# apollo510 register map
Vendor: Ambiq Micro; Series: Apollo; File version: 1.0
CPU: CM55 r1p1, little endian, MPU, FPU, double-precision FPU, DSP, I-cache, D-cache, VTOR, ITCM, DTCM, 4 interrupt priority bits, 0 interrupts, 8 SAU regions
Registers are 32-bit, read-write, reset 0x0 unless marked. A register's access mark holds for its fields unless they carry their own. Offsets are from the block's base; [hi:lo] are bit positions; 'fields as' and 'values as' point back to an identical list.

## I2S0 — I2S Master/Slave Module
Base 0x40208000
Same registers: I2S1 0x40209000
0x00 RXDATA — Read only access to the i2S receive data
  [31:0] RXSAMPLE — 32b audio sample from the internal receive FIFO. MSB is always in bit 31
0x04 RXCHANID — Read only received channel identification register
  [7:0] RXCHANID — Channel ID value 0-255.
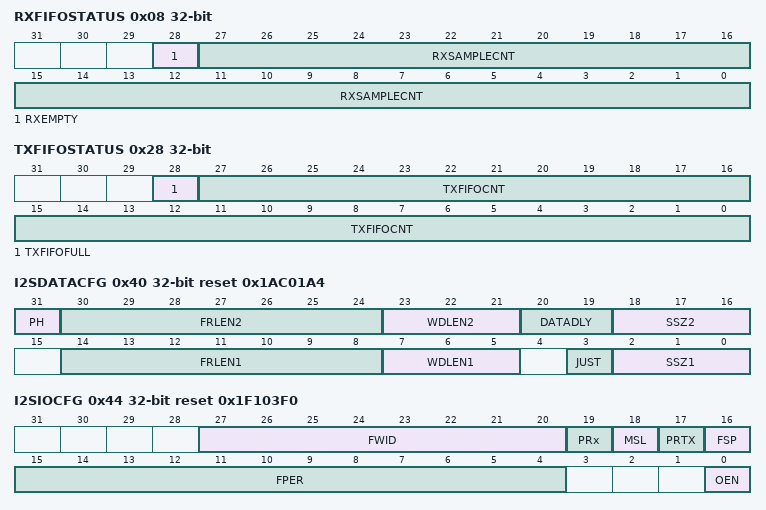
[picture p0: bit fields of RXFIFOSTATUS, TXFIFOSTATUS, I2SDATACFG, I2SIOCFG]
0x08 RXFIFOSTATUS — Holds the number of samples currently in the receive FIFO, and the empty condition flag
  [28] RXEMPTY — Receive FIFO empty bit. a 1 indicates the receive FIFO is empty.
  [27:0] RXSAMPLECNT — The count of the number of samples currently in the receive FIFO.
0x0C RXFIFOSIZE — Holds the size of the receive FIFO in samples
  [31:0] SIZE — Size of the receive FIFO in units of i2S samples. Read only value.
0x10 RXUPPERLIMIT — The number of samples required to be in the RX FIFO before asserting the RX_FFi interrupt bit
  [31:0] SIZE — When the I2S sample count stored within the receive FIFO reaches this value or is larger, the interrupt RX_FFi bit is asserted.
0x20 TXDATA — Write only register to hold the i2S sample to transmit via the write FIFO
  [31:0] TXSAMPLE — 32b I2S sample to send out of the I2S module via the external pins. All sample have the MSB in bit 31 regardless of number of bits per sample and data justification
0x24 TXCHANID — Channel ID used for the next audio sample to be written to the data transmission register
  [7:0] TXCHANID — Channel ID value 0-255.
0x28 TXFIFOSTATUS — Holds the number of samples currently in the transmit FIFO, and the full condition flag
  [28] TXFIFOFULL — Transmit FIFO full bit. a 1 indicates the transmit FIFO is full.
  [27:0] TXFIFOCNT — The count of the number of samples currently in the transmit FIFO.
0x2C TXFIFOSIZE — Holds the size of the transmit FIFO in samples
  [31:0] SIZE — Size of the transmit FIFO in units of I2S samples. Read only value.
0x30 TXLOWERLIMIT — Minimum number of samples have been reached in the transmit FIFO.
  [31:0] SIZE — When the number of sample in the TX FIFO goes below this value, the interrupt TX_FFi bit is asserted.
0x40 I2SDATACFG reset 0x1AC01A4 — Specifies the data format of I2S sub frames
  [31] PH — Read Phase Bit. 0: Single Phase frame; 1: Dual-Phase frame.
  [30:24] FRLEN2 — Number of channels in phase 2; 0: 1 Channel in phase 2, .. 0x7F: 128 channels in phase 2
    0=1CHLS (One channel in phase 2.); 1=2CHLS (Two channels in phase 2.); 2=3CHLS (Three channels in phase 2.); 3=4CHLS (Four channels in phase 2.); 4=5CHLS (Five channels in phase 2.); 5=6CHLS (Six channels in phase 2.); 6=7CHLS (Seven channels in phase 2.); 7=8CHLS (Eight channels in phase 2.); 127=128CHLS (128 channels in phase 2.)
  [23:21] WDLEN2 — Receive channel length in bits for phase 2. 0: 8b, 1: 12b, 2: 16b, 3: 20b, 4: 24b, 5: 32b, 6,7: Reserved
    0=8b (Receive channel length is 8 bits for phase 2.); 1=12b (Receive channel length is 12 bits for phase 2.); 2=16b (Receive channel length is 16 bits for phase 2.); 3=20b (Receive channel length is 20 bits for phase 2.); 4=24b (Receive channel length is 24 bits for phase 2.); 5=32b (Receive channel length is 32 bits for phase 2.)
  [20:19] DATADLY — Receive data delay bit count. Valid values are 0-2, 3 is reserved.
  [18:16] SSZ2 — Receive audio sample length for phase 2. 0: 8b, 1: 12b, 2: 16b, 3: 20b, 4: 24b, 5: 32b, 6,7: Reserved
    0=8b (Receive audio sample length is 8 bits for phase 2.); 1=12b (Receive audio sample length is 12 bits for phase 2.); 2=16b (Receive audio sample length is 16 bits for phase 2.); 3=20b (Receive audio sample length is 20 bits for phase 2.); 4=24b (Receive audio sample length is 24 bits for phase 2.); 5=32b (Receive audio sample length is 32 bits for phase 2.)
  [14:8] FRLEN1 — Number of channels in phase 1; 0: 1 Channel in phase 2, .. 0x7F: 128 channels in phase 1
    0=1CHLS (One channel in phase 1.); 1=2CHLS (Two channels in phase 1.); 2=3CHLS (Three channels in phase 1.); 3=4CHLS (Four channels in phase 1.); 4=5CHLS (Five channels in phase 1.); 5=6CHLS (Six channels in phase 1.); 6=7CHLS (Seven channels in phase 1.); 7=8CHLS (Eight channels in phase 1.); 127=128CHLS (128 channels in phase 1.)
  [7:5] WDLEN1 — Receive channel length in bits for phase 2. 0: 8b, 1: 12b, 2: 16b, 3: 20b, 4: 24b, 5: 32b, 6,7: Reserved
    0=8b (Receive channel length is 8 bits for phase 1.); 1=12b (Receive channel length is 12 bits for phase 1.); 2=16b (Receive channel length is 16 bits for phase 1.); 3=20b (Receive channel length is 20 bits for phase 1.); 4=24b (Receive channel length is 24 bits for phase 1.); 5=32b (Receive channel length is 32 bits for phase 1.)
  [3] JUST — Audio sample justification. 0: Left-justified, 1: Right-justified
  [2:0] SSZ1 — Receive audio sample length for phase 1. 0: 8b, 1: 12b, 2: 16b, 3: 20b, 4: 24b, 5: 32b, 6,7: Reserved
    0=8b (Receive audio sample length is 8 bits for phase 1.); 1=12b (Receive audio sample length is 12 bits for phase 1.); 2=16b (Receive audio sample length is 16 bits for phase 1.); 3=20b (Receive audio sample length is 20 bits for phase 1.); 4=24b (Receive audio sample length is 24 bits for phase 1.); 5=32b (Receive audio sample length is 32 bits for phase 1.)
0x44 I2SIOCFG reset 0x1F103F0 — Specified polarity and clock configuration of the I2S IPB clocks and IO signals
  [27:20] FWID — period of fsync/lr_clk in units of sclks
  [19] PRx — Receive clock edge polarity bit. 0: sdata is sampled on the rising edge of sclk. 1: sdata is sampled on the falling edge of sclk.
  [18] MSL — Master/Slave clock configuration. 0: External clock(sclk and lr_clk provided externally). 1: Internal clock (sclk and lr_clk sourced internally).
  [17] PRTX — Transmit clock edge polarity bit. 0: sdata is transmitted starting from the falling edge of sclk. 1: sdata is transmitted starting from the rising edge of sclk.
  [16] FSP — Polarity of fsync/lr_clk signal. 0: Active high. 1: Active low
  [15:4] FPER — Frame period in units of sclk. Period is FPER + 1 sclks in length. 0: 1 sclk, 0x3F: 64 sclks
  [0] OEN — Output enable for SDATA output
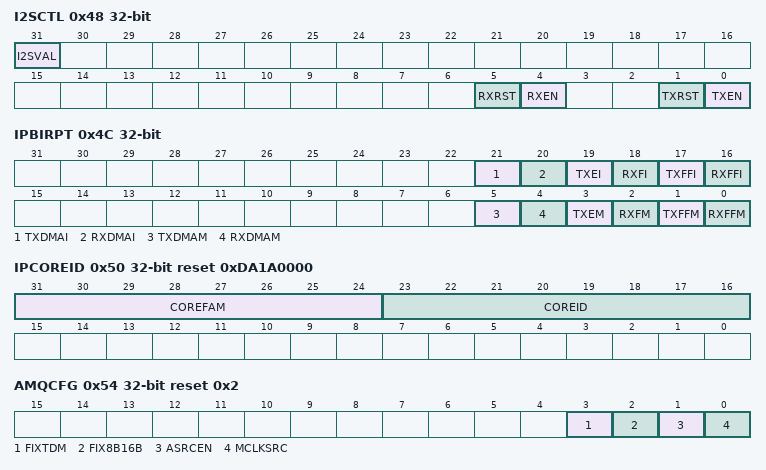
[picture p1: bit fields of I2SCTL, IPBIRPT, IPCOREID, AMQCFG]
0x48 I2SCTL — Specified polarity and clock configuration of the I2S IPB clocks and IO signals
  [31] I2SVAL — I2S validity bit mode. 1: RX data stored only when validity mask condition is asserted. 0: No validity mask conditions checking is done.
  [5] RXRST — Active high receiver reset signal. 1: Flush the RX FIFO
  [4] RXEN — Receive enable control. 1: Enables capture of serial audio, starting with first channel. 0: No receive data captured. For Full duplex operation, RXEN and TXEN MUST be set in a single register write access, or the Slave FSM may ignore one of the bit-field read-modify-write accesses. TXRST and RXRST must be cleared in advance.
  [1] TXRST — Transmit reset signal. 1 will reset the TX side registers and flush the TX FIFO.
  [0] TXEN — Transmit enable signal. 1 will enable the transmission of serial audio. For Full duplex operation, RXEN and TXEN MUST be set in a single register write access, or the Slave FSM may ignore one of the bit-field read-modify-write accesses. TXRST and RXRST must be cleared in advance.
0x4C IPBIRPT — Additional mask and status registers for the IPB core.
  [21] TXDMAI — TX dma interrupt
  [20] RXDMAI — RX dma interrupt
  [19] TXEI — TX Empty interrupt. TX unit attempted to read an empty FIFO
  [18] RXFI — RX Full interrupt. RX unit attempted to write to a full FIFO
  [17] TXFFI — Transmit fifo low limit interrupt
  [16] RXFFI — Receive fifo high limit interrupt
  [5] TXDMAM — Transmit FIFO interrupt mask. Will assert interrupt when = 1 and cimdmareq_tx is asserted
  [4] RXDMAM — Receive FIFO interrupt mask. Will assert interrupt when = 1 and cimdmareq_rx is asserted
  [3] TXEM — Transmit FIFO interrupt mask. Will assert interrupt when = 1 and TXEI is asserted
  [2] RXFM — Receive FIFO interrupt mask. Will assert interrupt when = 1 and RXFI is asserted
  [1] TXFFM — Transmit FIFO interrupt mask. Will assert interrupt when = 1 and TXFFI is asserted
  [0] RXFFM — Receive FIFO interrupt mask. Will assert interrupt when = 1 and RXFFI is asserted
0x50 IPCOREID reset 0xDA1A0000 — Returns the core ID of the IPB core, and used to write the I2S validity mask.
  [31:24] COREFAM — Core Family. Also bit 31 is used to set the I2S validity bit when a write is done.
  [23:16] COREID — Core ID of the IPB core
0x54 AMQCFG reset 0x2 — Control the enablement of the ASRC module and the source of the MCLK used in the IPB core.
  [3] FIXTDM — FIXTDM bug 1: Enabled. 0: Disabled/Bypassed
  [2] FIX8B16B — FIX8B16B bug 1: Enabled. 0: Disabled/Bypassed
  [1] ASRCEN — ASRC sub module enable. 0: Enabled. 1: Disabled/Bypassed
  [0] MCLKSRC — MCLK source. 1: Output of nco_clk divider. 0: MCLK from ambiq clock configuration directly
0x60 INTDIV — Integer divide value for the nco_clk divider
  [31:0] INTDIV — Integer divide value for internal clock divider
0x64 FRACDIV — Fractional divide value for the nco_clk divider
  [31:0] FRACDIV — Fractional divide value for internal clock divider
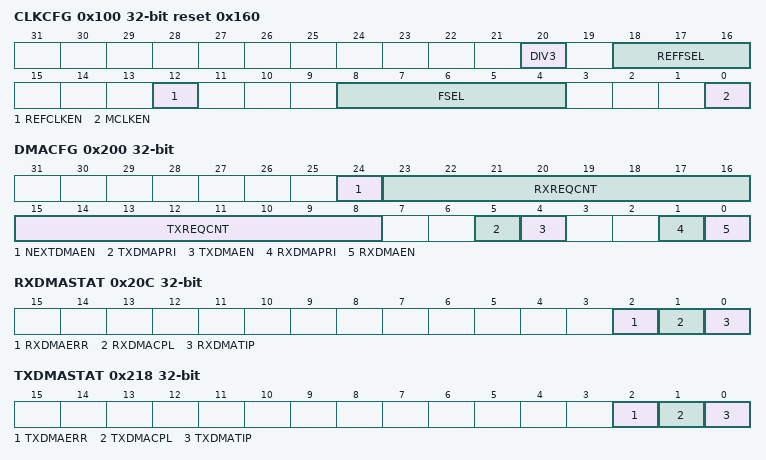
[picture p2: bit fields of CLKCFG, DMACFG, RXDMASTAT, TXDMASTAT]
0x100 CLKCFG reset 0x160 — Provides clock selection and control for I2S clocks
  [20] DIV3 — 0: no change to the clock selected by FSEL 1: frequency divide-by-3 of the clock selected by FSEL
  [18:16] REFFSEL — FUTURE USE Select the input clock frequency for the ref_clk. 0: HFRC_48MHz 1: HFRC_48MHz_GATED 2: XT_24MHz 3: HFRC2_48MHz
  [12] REFCLKEN — FUTURE USE Enable for the reference clock
  [8:4] FSEL — Select the input clock frequency for the MCLK.Whenever changing the clock source here, the MISC_HFRC2FRC bit in the CLKGEN module must first be set. The sequence for changing the clock source regardless of clock selection is to first force HFRC2 on by setting the CLKGEN_MISC_HFRC2FRC bit, select the clock source in this field, clear the CLKGEN_MISC_HFRC2FRC bit only if HFRC2 is NOT selected, and then engage the peripheral.If HFRC2 is the clock source, then shutting the module down cleanly requires switching to HFRC, for example, and then disabling the HFRC2 by clearing the CLKGEN_MISC_HFRC2FRC bit. 0: HFRC2_62MHz 1: HFRC2_31MHz 2: HFRC2_16MHz 3: HFRC2_8MHz 4: HFRC2_4MHz 5: HFRC2_2MHz 6: HFRC2_977KHz 7: HFRC2_488KHz 8: HFRC_24MHz 9: HFRC_12MHz 10: HFRC_6MHz 11: HFRC_3MHz 12: HFRC_1_5MHz 13: HFRC_750KHz 14: HFRC_375KHz 15: XTHS_EXTREF_CLK 16: XTHS_16MHz 17: XTHS_8MHz 18: XTHS_4MHz 19: XTHS_2MHz 20: XTHS_1MHz 21: XTHS_500KHz 22: HFRC_48MHz
  [0] MCLKEN — Enable for the master audio clock.
0x200 DMACFG — Configuration control of the DMA process, including the direction of DMA, and enablement of DMA
  [24] NEXTDMAEN — Enable next DMA job auto-load feature
  [23:16] RXREQCNT — Number of blocks of samples transferred before asserting the RXREQCNT interrupt signal. A block is 8 samples. The interrupt will assert if enabled and after RXREQCNT blocks of data has been transferred from the I2S into the device. A value of 0 will cause the assertion of the interrupt for every block of transfer done.
  [15:8] TXREQCNT — Number of blocks of samples transferred before asserting the TXREQCNT interrupt signal. A block is 8 samples. The interrupt will assert if enabled and after TXREQCNT blocks of data has been transferred to the I2S module from the device. A value of 0 will cause the assertion of the interrupt for every block of transfer done.
  [5] TXDMAPRI — Sets the Priority of the TXDMA request
    0=LOW (Low Priority (service as best effort)); 1=HIGH (High Priority (service immediately))
  [4] TXDMAEN — DMA Enable for TX channel. Setting this bit to EN will start the DMA operation. This should be the last DMA related register set prior to issuing the command
    0=DIS (Disable TXDMA Function); 1=EN (Enable TXDMA Function)
  [1] RXDMAPRI — Sets the Priority of the RXDMA request
    values as TXDMAPRI
  [0] RXDMAEN — DMA Enable for RX channel. Setting this bit to EN will start the DMA operation. This should be the last DMA related register set prior to issuing the command
    0=DIS (Disable RXDMA Function); 1=EN (Enable RXDMA Function)
0x204 RXDMATOTCNT — Contains the total count of samples to be stored for the current RX DMA operation. This register is updated as DMA beats complete.
  [11:0] RXTOTCNT — Number of 32b audio samples to transfer for RX DMA.
0x208 RXDMAADDR — The address which the DMA operation will store the incoming audio samples. This address is updated as the samples are stored.
  [31:0] RXTARGADDR — Address bits of the target byte address for source of RX write DMA.
0x20C RXDMASTAT — Status of the RX DMA operation currently in progress.
  [2] RXDMAERR — RX DMA Error. This active high bit signals an error was encountered during the DMA operation. The bit can be cleared by writing to 0. Once set, this bit will remain set until cleared by software.
  [1] RXDMACPL — RX DMA Transfer Complete. This signals the end of the DMA operation. This bit can be cleared by writing to 0, and will also be cleared when a new DMA is started.
  [0] RXDMATIP — RX DMA Transfer In Progress indicator. 1 will indicate that a DMA transfer is active. The DMA transfer may be waiting on data, transferring data, or waiting for priority. All of these will be indicated with a 1. A 0 will indicate that the DMA is fully complete and no further transactions will be done. This bit is read only.
0x210 TXDMATOTCNT — Contains the total count of samples to be read and transmitted for the current TX DMA operation. This register is updated as DMA beats complete.
  [11:0] TXTOTCNT — Number of 32b audio samples to transmit
0x214 TXDMAADDR — The address which the DMA operation will fetch the audio samples. This address is updated as the samples are stored.
  [31:0] TXTARGADDR — Address bits of the target byte address for source of TX write DMA.
0x218 TXDMASTAT — Status of the TX DMA operation currently in progress.
  [2] TXDMAERR — TX DMA Error. This active high bit signals an error was encountered during the DMA operation. The bit can be cleared by writing to 0. Once set, this bit will remain set until cleared by software.
  [1] TXDMACPL — TX DMA Transfer Complete. This signals the end of the DMA operation. This bit can be cleared by writing to 0, and will also be cleared when a new DMA is started.
  [0] TXDMATIP — TX DMA Transfer In Progress indicator. 1 will indicate that a DMA transfer is active. The DMA transfer may be waiting on data, transferring data, or waiting for priority. All of these will be indicated with a 1. A 0 will indicate that the DMA is fully complete and no further transactions will be done. This bit is read only.
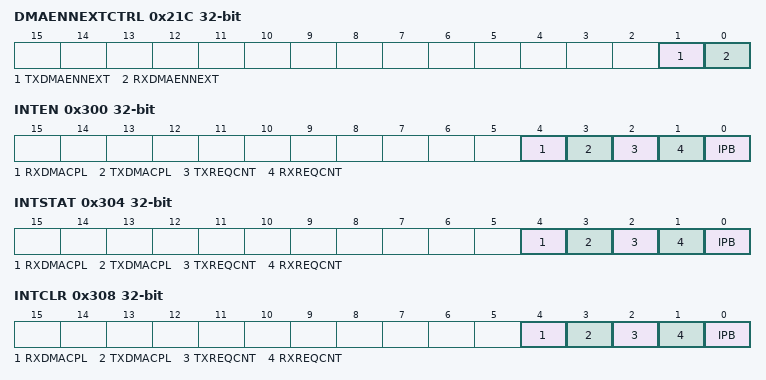
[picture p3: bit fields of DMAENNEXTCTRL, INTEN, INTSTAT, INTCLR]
0x21C DMAENNEXTCTRL — To enable next DMA job
  [1] TXDMAENNEXT — Indicate to HW the next TX DMA job. TXTARGADDRNEXT and TXTOTCNTNEXT needs to be valid before setting this bit. HW will autoclear this bit when this job is serviced. SW should read back this bit after setting it. If it reads back 0, it means SW can load another set of TXTARGADDRNEXT and TXTOTCNTNEXT and set this bit again. If it reads back 1, it means the HW is servicing a DMA job, and the next DMA job is yet to be loaded. SW needs to wait for TXDMACPL interrupt to setup the next job.
  [0] RXDMAENNEXT — Indicate to HW the next RX DMA job. RXTARGADDRNEXT and RXTOTCNTNEXT needs to be valid before setting this bit. HW will autoclear this bit when this job is serviced. SW should read back this bit after setting it. If it reads back 0, it means SW can load another set of RXTARGADDRNEXT and RXTOTCNTNEXT and set this bit again. If it reads back 1, it means the HW is servicing a DMA job, and the next DMA job is yet to be loaded. SW needs to wait for RXDMACPL interrupt to setup the next job.
0x220 RXDMATOTCNTNEXT — Contains the total count of samples to be stored for the next RX DMA operation.
  [11:0] RXTOTCNTNEXT — Number of 32b audio samples to transfer for next RX DMA.
0x224 RXDMAADDRNEXT — The address which the next DMA operation will store the incoming audio samples.
  [31:0] RXTARGADDRNEXT — Address bits of the target byte address for source of next RX write DMA.
0x228 TXDMATOTCNTNEXT — Contains the total count of samples to be read and transmitted for the next TX DMA operation.
  [11:0] TXTOTCNTNEXT — Number of 32b audio samples to transmit in next TX DMA
0x22C TXDMAADDRNEXT — The address which the next DMA operation will fetch the audio samples.
  [31:0] TXTARGADDRNEXT — Address bits of the target byte address for source of next TX write DMA.
0x230 STATUS — I2S Module Status
  [0] TBD — To Be determined.
0x300 INTEN — Set bits in this register to allow this module to generate the corresponding interrupt.
  [4] RXDMACPL — A RX dma operation has completed
  [3] TXDMACPL — A TX dma operation has completed
  [2] TXREQCNT — The I2S module has asserted the dma read request, based on TX fifo level.
  [1] RXREQCNT — The I2S module has completed RXREQCNT number of DMA transfers of size 8 samples. This interrupt allows servicing of buffers at a programmable location within the overall DMA transfer.
  [0] IPB — Interrupt from I2S module
0x304 INTSTAT — Read bits from this register to discover the cause of a recent interrupt.
  fields as INTEN
0x308 INTCLR — Write a 1 to a bit in this register to clear the interrupt status associated with that bit.
  fields as INTEN
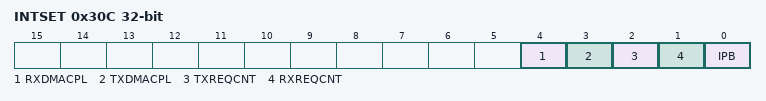
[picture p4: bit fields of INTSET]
0x30C INTSET — Write a 1 to a bit in this register to instantly generate an interrupt from this module. (Generally used for testing purposes).
  fields as INTEN
